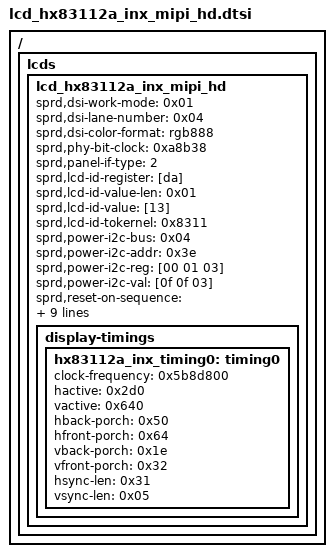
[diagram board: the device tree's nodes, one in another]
/ { lcds {
	lcd_hx83112a_inx_mipi_hd: lcd_hx83112a_inx_mipi_hd {

		sprd,dsi-work-mode = <0x01>; /* video burst mode*/
		sprd,dsi-lane-number = <0x04>;
		sprd,dsi-color-format = "rgb888";

		sprd,phy-bit-clock = <0xa8b38>;	/* kbps */

		/* panel interface type: 2:MIPI; 3:SPI */
		sprd,panel-if-type = <2>;

		/*----Id register ----*/
		sprd,lcd-id-register = [da];
		sprd,lcd-id-value-len = <0x01>;
		sprd,lcd-id-value = [13];
		sprd,lcd-id-tokernel = <0x8311>;

		/*---Bias Power---*/
		sprd,power-i2c-bus = <0x04>;
		sprd,power-i2c-addr = <0x3e>;
		sprd,power-i2c-reg = [00 01 03];
		sprd,power-i2c-val = [0f 0f 03];

		sprd,reset-on-sequence = <0x01 0x05 0x00 0x05 0x01 0x14>;
		sprd,reset-off-sequence = <0x01 0x05>;

		sprd,use-dcs-write;

		sprd,initial-command = [
			39 00 00 04 B9 83 11 2A
			39 00 00 05 CF 00 14 00 C0
			39 00 00 05 C4 06 04 04 81
			39 00 00 02 CC 08
			39 00 00 05 C9 04 0A 8C 01
			39 00 00 09 B1 08 29 29 80 80 4F 4A AA
			39 00 00 10 B2 00 02 00 62 40 00 08 30 14 11 15 00 10 A3 87
			39 00 00 03 D2 2C 2C
			39 00 00 1C B4 0B C8 0B C8 00 00 0B CD 00 00 0B CD 00 FF 00 FF 00 00 0C 0F 00 30 08 0D 0F 00 30
			39 00 00 09 C7 00 00 04 E0 33 00 20 40
			39 00 00 2B D3 C0 00 00 00 00 00 00 05 05 04 04 00 1F 0B 0B 0B 0B 32 10 0A 00 0A 32 16 23 06 23 32 10 06 00 06 00 00 00 00 00 00 00 0A 06 4B
			39 00 00 02 BD 01
			39 00 00 04 CB 25 11 01
			39 00 00 02 BD 00
			39 00 00 31 D5 18 18 18 18 18 18 18 18 18 18 18 18 18 18 18 18 18 18 18 18 31 31 30 30 2F 2F 20 20 00 00 01 01 02 02 03 03 04 04 40 40 19 19 18 18 18 18 18 18
			39 00 00 31 D6 18 18 18 18 18 18 18 18 18 18 18 18 18 18 18 18 18 18 18 18 31 31 30 30 2F 2F 20 20 04 04 03 03 02 02 01 01 00 00 40 40 19 19 18 18 18 18 18 18
			39 00 00 19 D8 AA AA AA AF FE EA AA AA AA AF FE EA AA AA AA AA AA EA AA AA AA AA AA EA
			39 00 00 02 BD 01
			39 00 00 19 D8 AA AA AF EF FF AA AA AA AF EF FF AA AA AA AF EF FF AA AA AA AF EF FF AA
			39 00 00 02 BD 02
			39 00 00 0D D8 AA AA AF EF FF AA AA AA AF EF FF AA
			39 00 00 02 BD 03
			39 00 00 19 D8 AA AA AA AF FE EA AA AA AA AF FE EA AA AA AF FF FF AA AA AA AF FF FF AA
			39 00 00 02 BD 00
			39 00 00 18 E7 0F 0F 1E 72 1E 72 00 50 02 02 00 00 02 02 02 05 14 14 32 B9 23 B9 08
			39 00 00 02 BD 01
			39 00 00 09 E7 02 00 64 01 6E 0E 4B 0F
			39 00 00 02 BD 02
			39 00 00 1E E7 00 00 08 00 01 00 00 00 00 00 00 00 00 00 00 00 00 00 00 00 00 00 04 00 00 00 00 02 00
			39 00 00 02 BD 00
			39 00 00 02 E9 C3
			39 00 00 03 CB D2 28
			39 00 00 02 E9 3F
			39 00 00 02 C1 01
			39 00 00 02 BD 01
			39 00 00 02 E9 C8
			39 00 00 02 D3 81
			39 00 00 02 E9 3F
			39 00 00 02 BD 00
			39 00 00 03 C1 01 00
			39 00 00 02 BD 01
			39 00 00 3A C1 FF F9 F5 F0 EB E6 E1 D8 D3 CF C9 C4 BF BB B6 B0 AC A7 A2 99 90 87 7F 77 6F 67 60 59 51 4A 44 3E 37 30 29 22 1C 16 0F 09 06 05 02 01 00 34 BD 8A D3 18 7A F8 D8 0B 5A 4E 40
			39 00 00 02 BD 02
			39 00 00 3A C1 FF F9 F5 F0 EB E6 E1 D8 D3 CF C9 C4 BF BB B6 B0 AC A7 A2 99 90 87 7F 77 6F 67 60 59 51 4A 44 3E 37 30 29 22 1C 16 0F 09 06 05 02 01 00 34 BD 8A D3 18 7A F8 D8 0B 5A 4E 40
			39 00 00 02 BD 03
			39 00 00 3A C1 FF F9 F5 F0 EB E6 E1 D8 D3 CF C9 C4 BF BB B6 B0 AC A7 A2 99 90 87 7F 77 6F 67 60 59 51 4A 44 3E 37 30 29 22 1C 16 0F 09 06 05 02 01 00 34 BD 8A D3 18 7A F8 D8 0B 5A 4E 40
			39 00 00 02 BD 00
			39 00 00 03 CE 05 10
			39 00 00 3D E6 22 55 22 00 AA 11 22 11 00 AA C0 00 80 C0 6B 33 66 33 00 AA 33 66 33 00 AA 33 66 33 00 AA 33 66 33 00 AA 33 66 33 00 AA 33 66 33 00 AA 33 66 33 00 AA 33 66 33 00 AA 33 66 33 00 AA
			39 00 00 0C E5 06 00 05 05 FE 00 00 00 00 00 00
			05 78 00 01 11
			39 00 00 02 35 00
			39 00 00 03 5E 00 04
			39 00 00 03 51 00 00
			39 00 00 05 C9 04 07 29 01
			39 0A 00 02 55 00
			39 00 00 02 53 24
			05 32 00 01 29
			];
			
		sprd,sleep-in-command = [15 32 00 01 28 15 96 00 01 10];
		sprd,sleep-out-command = [15 78 00 01 11 15 32 00 01 29];

		display-timings {
			hx83112a_inx_timing0: timing0 {
				clock-frequency = <0x5b8d800>;
				hactive = <0x2d0>;
				vactive = <0x640>;
				hback-porch = <0x50>;
				hfront-porch = <0x64>;
				vback-porch = <0x1e>;
				vfront-porch = <0x32>;
				hsync-len = <0x31>;
				vsync-len = <0x05>;
			};
		};
	};
};};
